# STM32L4A6ZGT6P register map
File version: 1.0
STM32L4A6AGI6,STM32L4A6AGI6P,STM32L4A6QGI6,STM32L4A6QGI6P,STM32L4A6RGT6,STM32L4A6RGT6P,STM32L4A6RGT7,STM32L4A6RGT7P,STM32L4A6VGT6,STM32L4A6VGT6P,STM32L4A6VGY6,STM32L4A6VGY6P,STM32L4A6ZGT6,STM32L4A6ZGT6P
Registers are 32-bit, access not given, reset 0x0 unless marked. A register's access mark holds for its fields unless they carry their own. Offsets are from the block's base; lines under a group give offsets from that group; [hi:lo] are bit positions; {n}, {i} and the like mark numbered series; 'fields as' and 'values as' point back to an identical list; <NAME> marks a mode.

## Memory map
0x40000000 TIM2
0x40000400 TIM3
0x40000800 TIM4
0x40000C00 TIM5
0x40001000 TIM6
0x40001400 TIM7
0x40002400 LCD
0x40002800 RTC
0x40002C00 WWDG
0x40003000 IWDG
0x40003800 SPI2
0x40003C00 SPI3
0x40004400 USART2
0x40004800 USART3
0x40004C00 UART4
0x40005000 UART5
0x40005400 I2C1
0x40005800 I2C2
0x40005C00 I2C3
0x40006000 CRS
0x40006400 CAN
0x40006400 CAN1
0x40006800 CAN2
0x40007000 PWR
0x40007400 DAC
0x40007400 DAC1
0x40007800 OPAMP
0x40007800 OPAMP1
0x40007800 OPAMP12_COMMON
0x40007810 OPAMP2
0x40007C00 LPTIM1
0x40008000 LPUART1
0x40008400 I2C4
0x40008800 SWPMI1
0x40009400 LPTIM2
0x40010000 SYSCFG
0x40010030 VREFBUF
0x40010200 COMP1
0x40010204 COMP2
0x40010204 COMP12_COMMON
0x40010400 EXTI
0x40011C00 FIREWALL
0x40012800 SDMMC1
0x40012C00 TIM1
0x40013000 SPI1
0x40013400 TIM8
0x40013800 USART1
0x40014000 TIM15
0x40014400 TIM16
0x40014800 TIM17
0x40015400 SAI1
0x40015800 SAI2
0x40016000 DFSDM1
0x40020000 DMA1
0x400200A8 DMA1_CSELR
0x40020400 DMA2
0x400204A8 DMA2_CSELR
0x40021000 RCC
0x40022000 FLASH
0x40023000 CRC
0x40024000 TSC
0x4002B000 DMA2D
0x48000000 GPIOA
0x48000400 GPIOB
0x48000800 GPIOC
0x48000C00 GPIOD
0x48001000 GPIOE
0x48001400 GPIOF
0x48001800 GPIOG
0x48001C00 GPIOH
0x48002000 GPIOI
0x50000000 USB_OTG_FS
0x50040000 ADC1
0x50040100 ADC2
0x50040200 ADC3
0x50040300 ADC123_COMMON
0x50050000 DCMI
0x50060000 AES
0x50060400 HASH
0x50060710 HASH_DIGEST
0x50060800 RNG
0xA0000000 FMC_Bank1_R
0xA0000080 FMC_Bank3_R
0xA0000104 FMC_Bank1E_R
0xA0001000 QUADSPI
0xE0042000 DBGMCU

## TIM2
Base 0x40000000
Same registers: TIM3 0x40000400, TIM4 0x40000800, TIM5 0x40000C00, TIM6 0x40001000, TIM7 0x40001400, TIM1 0x40012C00, TIM8 0x40013400, TIM15 0x40014000, TIM16 0x40014400, TIM17 0x40014800
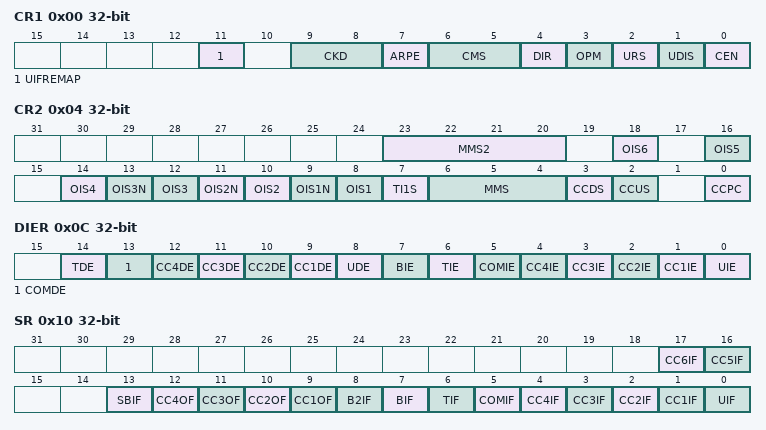
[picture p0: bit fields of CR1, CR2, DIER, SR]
0x00 CR1
  [11] UIFREMAP, [9:8] CKD, [7] ARPE, [6:5] CMS, [4] DIR, [3] OPM, [2] URS, [1] UDIS, [0] CEN
0x04 CR2
  [23:20] MMS2, [2n+6] OIS{n} (n=1..6), [13] OIS3N, [11] OIS2N, [9] OIS1N, [7] TI1S, [6:4] MMS, [3] CCDS, [2] CCUS, [0] CCPC
0x08 SMCR
  [15] ETP, [14] ECE, [13:12] ETPS, [11:8] ETF, [7] MSM, [6:4] TS, [3] OCCS, [16:0] SMS
0x0C DIER
  [14] TDE, [13] COMDE, [n+8] CC{n}DE (n=1..4), [8] UDE, [7] BIE, [6] TIE, [5] COMIE, [n] CC{n}IE (n=1..4), [0] UIE
0x10 SR
  [17] CC6IF, [16] CC5IF, [13] SBIF, [n+8] CC{n}OF (n=1..4), [8] B2IF, [7] BIF, [6] TIF, [5] COMIF, [n] CC{n}IF (n=1..4), [0] UIF
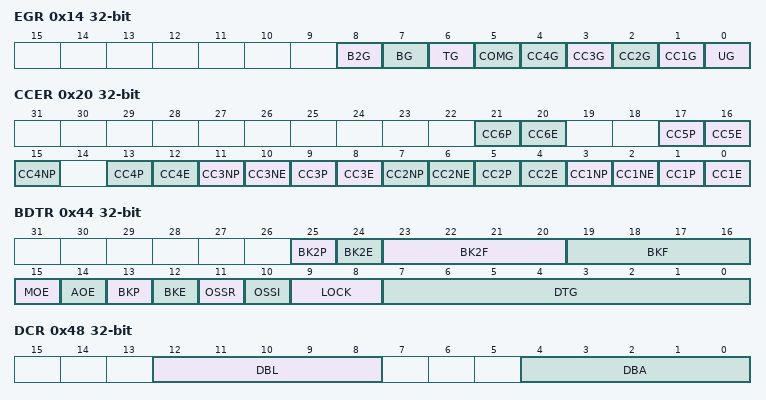
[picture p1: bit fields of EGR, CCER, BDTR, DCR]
0x14 EGR
  [8] B2G, [7] BG, [6] TG, [5] COMG, [n] CC{n}G (n=1..4), [0] UG
0x18 CCMR1
  [15] OC2CE, [24:12] OC2M, [11] OC2PE, [10] OC2FE, [9:8] CC2S, [7] OC1CE, [16:4] OC1M, [3] OC1PE, [2] OC1FE, [1:0] CC1S
0x1C CCMR2
  [15] OC4CE, [24:12] OC4M, [11] OC4PE, [10] OC4FE, [9:8] CC4S, [7] OC3CE, [16:4] OC3M, [3] OC3PE, [2] OC3FE, [1:0] CC3S
0x20 CCER
  [4n-3] CC{n}P (n=1..6), [4n-4] CC{n}E (n=1..6), [4n-1] CC{n}NP (n=1..4), [10] CC3NE, [6] CC2NE, [2] CC1NE
0x24 CNT
  [31] UIFCPY, [31:0] CNT
0x28 PSC
  [15:0] PSC
0x2C ARR
0x30 RCR
  [15:0] REP
{0x30+4i} CCR{i} (i=1..4)
  [15:0] CCR{i}
0x44 BDTR
  [25] BK2P, [24] BK2E, [23:20] BK2F, [19:16] BKF, [15] MOE, [14] AOE, [13] BKP, [12] BKE, [11] OSSR, [10] OSSI, [9:8] LOCK, [7:0] DTG
0x48 DCR
  [12:8] DBL, [4:0] DBA
0x4C DMAR
  [15:0] DMAB
0x50 OR1
0x54 CCMR3
  [15] OC6CE, [24:12] OC6M, [11] OC6PE, [10] OC6FE, [7] OC5CE, [16:4] OC5M, [3] OC5PE, [2] OC5FE
0x58 CCR5
  [31] GC5C3, [30] GC5C2, [29] GC5C1, [31:0] CCR5
0x5C CCR6
  [15:0] CCR6
0x60 OR2
0x64 OR3

## LCD
Base 0x40002400
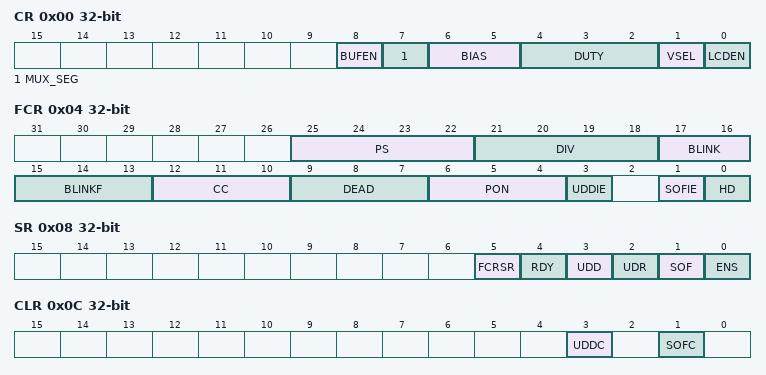
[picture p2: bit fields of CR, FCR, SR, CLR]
0x00 CR
  [8] BUFEN, [7] MUX_SEG, [6:5] BIAS, [4:2] DUTY, [1] VSEL, [0] LCDEN
0x04 FCR
  [25:22] PS, [21:18] DIV, [17:16] BLINK, [15:13] BLINKF, [12:10] CC, [9:7] DEAD, [6:4] PON, [3] UDDIE, [1] SOFIE, [0] HD
0x08 SR
  [5] FCRSR, [4] RDY, [3] UDD, [2] UDR, [1] SOF, [0] ENS
0x0C CLR
  [3] UDDC, [1] SOFC
0x14 RAM.0
  [31:0] SEGMENT_DATA
0x18 RAM.1
  [31:0] SEGMENT_DATA
0x1C RAM.2
  [31:0] SEGMENT_DATA
0x20 RAM.3
  [31:0] SEGMENT_DATA
0x24 RAM.4
  [31:0] SEGMENT_DATA
0x28 RAM.5
  [31:0] SEGMENT_DATA
0x2C RAM.6
  [31:0] SEGMENT_DATA
0x30 RAM.7
  [31:0] SEGMENT_DATA
0x34 RAM.8
  [31:0] SEGMENT_DATA
0x38 RAM.9
  [31:0] SEGMENT_DATA
0x3C RAM.10
  [31:0] SEGMENT_DATA
0x40 RAM.11
  [31:0] SEGMENT_DATA
0x44 RAM.12
  [31:0] SEGMENT_DATA
0x48 RAM.13
  [31:0] SEGMENT_DATA
0x4C RAM.14
  [31:0] SEGMENT_DATA
0x50 RAM.15
  [31:0] SEGMENT_DATA
